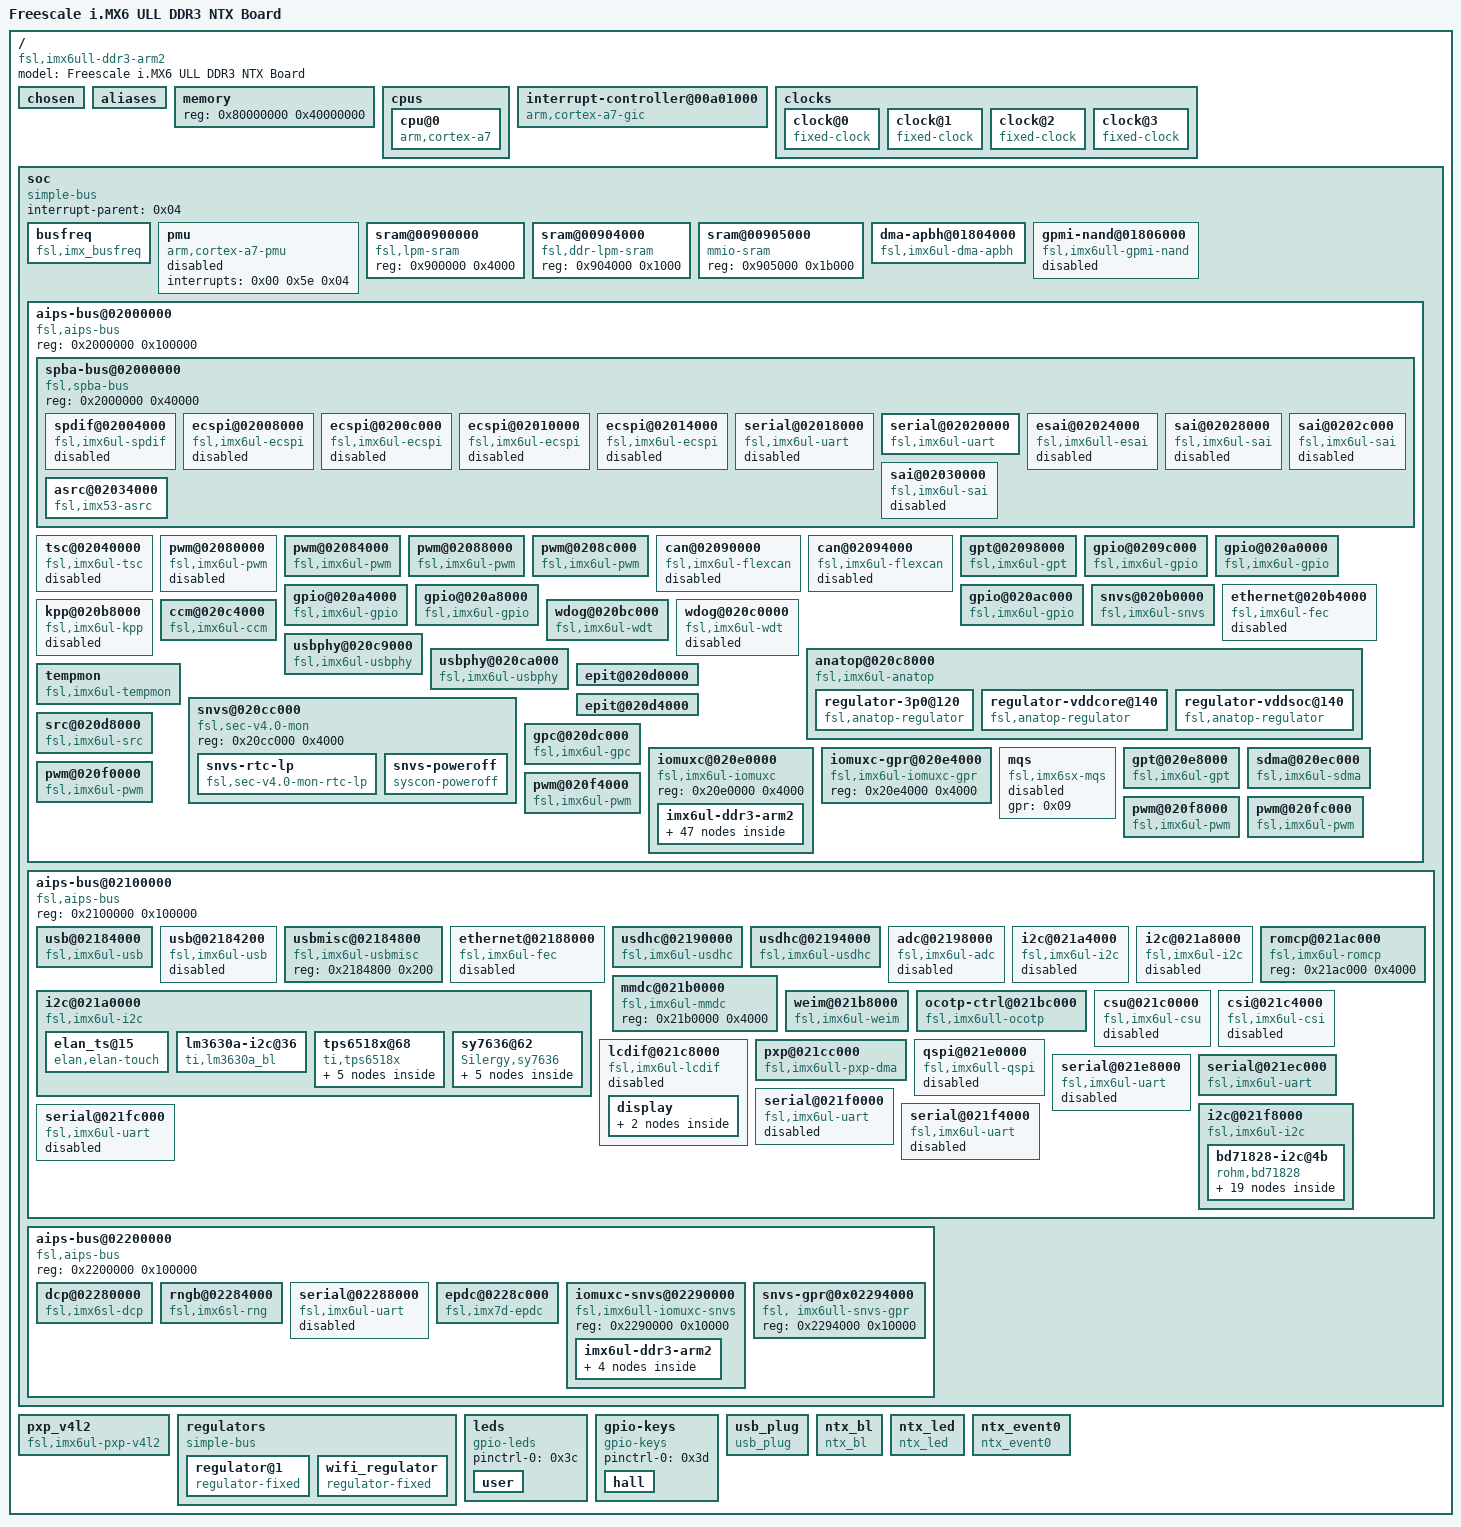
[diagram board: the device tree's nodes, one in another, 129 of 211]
/dts-v1/;

/ {
	#address-cells = <0x01>;
	#size-cells = <0x01>;
	model = "Freescale i.MX6 ULL DDR3 NTX Board";
	compatible = "fsl,imx6ull-ddr3-arm2\0fsl,imx6ull";

	chosen {
		stdout-path = "/soc/aips-bus@02000000/spba-bus@02000000/serial@02020000";
	};

	aliases {
		can0 = "/soc/aips-bus@02000000/can@02090000";
		can1 = "/soc/aips-bus@02000000/can@02094000";
		ethernet0 = "/soc/aips-bus@02100000/ethernet@02188000";
		ethernet1 = "/soc/aips-bus@02000000/ethernet@020b4000";
		gpio0 = "/soc/aips-bus@02000000/gpio@0209c000";
		gpio1 = "/soc/aips-bus@02000000/gpio@020a0000";
		gpio2 = "/soc/aips-bus@02000000/gpio@020a4000";
		gpio3 = "/soc/aips-bus@02000000/gpio@020a8000";
		gpio4 = "/soc/aips-bus@02000000/gpio@020ac000";
		i2c0 = "/soc/aips-bus@02100000/i2c@021a0000";
		i2c1 = "/soc/aips-bus@02100000/i2c@021a4000";
		i2c2 = "/soc/aips-bus@02100000/i2c@021a8000";
		i2c3 = "/soc/aips-bus@02100000/i2c@021f8000";
		mmc0 = "/soc/aips-bus@02100000/usdhc@02194000";
		mmc1 = "/soc/aips-bus@02100000/usdhc@02190000";
		serial0 = "/soc/aips-bus@02000000/spba-bus@02000000/serial@02020000";
		serial1 = "/soc/aips-bus@02100000/serial@021e8000";
		serial2 = "/soc/aips-bus@02100000/serial@021ec000";
		serial3 = "/soc/aips-bus@02100000/serial@021f0000";
		serial4 = "/soc/aips-bus@02100000/serial@021f4000";
		serial5 = "/soc/aips-bus@02100000/serial@021fc000";
		serial6 = "/soc/aips-bus@02000000/spba-bus@02000000/serial@02018000";
		serial7 = "/soc/aips-bus@02200000/serial@02288000";
		spi0 = "/soc/aips-bus@02000000/spba-bus@02000000/ecspi@02008000";
		spi1 = "/soc/aips-bus@02000000/spba-bus@02000000/ecspi@0200c000";
		spi2 = "/soc/aips-bus@02000000/spba-bus@02000000/ecspi@02010000";
		spi3 = "/soc/aips-bus@02000000/spba-bus@02000000/ecspi@02014000";
		usbphy0 = "/soc/aips-bus@02000000/usbphy@020c9000";
		usbphy1 = "/soc/aips-bus@02000000/usbphy@020ca000";
	};

	memory {
		device_type = "memory";
		reg = <0x80000000 0x40000000>;
	};

	cpus {
		#address-cells = <0x01>;
		#size-cells = <0x00>;

		cpu@0 {
			compatible = "arm,cortex-a7";
			device_type = "cpu";
			reg = <0x00>;
			clock-latency = <0xee6c>;
			operating-points = <0xdbba0 0x1312d0 0xc15c0 0x124f80 0x80e80 0x11edd8 0x60ae0 0x11edd8 0x30570 0x11edd8>;
			fsl,soc-operating-points = <0xdbba0 0x1312d0 0xc15c0 0x124f80 0x80e80 0x11edd8 0x60ae0 0x11edd8 0x30570 0x11edd8>;
			fsl,low-power-run;
			clocks = <0x01 0x5d 0x01 0x1a 0x01 0x26 0x01 0xdb 0x01 0x38 0x01 0x39 0x01 0x19 0x01 0x12 0x01 0x0b 0x01 0x04 0x01 0x03>;
			clock-names = "arm\0pll2_bus\0pll2_pfd2_396m\0secondary_sel\0step\0pll1_sw\0pll1_sys\0pll1_bypass\0pll1\0pll1_bypass_src\0osc";
			arm-supply = <0x02>;
			soc-supply = <0x03>;
		};
	};

	interrupt-controller@00a01000 {
		compatible = "arm,cortex-a7-gic";
		#interrupt-cells = <0x03>;
		interrupt-controller;
		reg = <0xa01000 0x1000 0xa02000 0x100>;
		linux,phandle = <0x13>;
		phandle = <0x13>;
	};

	clocks {
		#address-cells = <0x01>;
		#size-cells = <0x00>;

		clock@0 {
			compatible = "fixed-clock";
			reg = <0x00>;
			#clock-cells = <0x00>;
			clock-frequency = <0x8000>;
			clock-output-names = "ckil";
			linux,phandle = <0x0b>;
			phandle = <0x0b>;
		};

		clock@1 {
			compatible = "fixed-clock";
			reg = <0x01>;
			#clock-cells = <0x00>;
			clock-frequency = <0x16e3600>;
			clock-output-names = "osc";
			linux,phandle = <0x0c>;
			phandle = <0x0c>;
		};

		clock@2 {
			compatible = "fixed-clock";
			reg = <0x02>;
			#clock-cells = <0x00>;
			clock-frequency = <0x00>;
			clock-output-names = "ipp_di0";
			linux,phandle = <0x0d>;
			phandle = <0x0d>;
		};

		clock@3 {
			compatible = "fixed-clock";
			reg = <0x03>;
			#clock-cells = <0x00>;
			clock-frequency = <0x00>;
			clock-output-names = "ipp_di1";
			linux,phandle = <0x0e>;
			phandle = <0x0e>;
		};
	};

	soc {
		#address-cells = <0x01>;
		#size-cells = <0x01>;
		compatible = "simple-bus";
		interrupt-parent = <0x04>;
		ranges;

		busfreq {
			compatible = "fsl,imx_busfreq";
			clocks = <0x01 0x26 0x01 0x35 0x01 0x1a 0x01 0x5d 0x01 0x1b 0x01 0x55 0x01 0x3c 0x01 0x5e 0x01 0x3e 0x01 0x03 0x01 0x60 0x01 0xd4 0x01 0x56 0x01 0x3d 0x01 0x5f 0x01 0x3f 0x01 0x38 0x01 0xa3 0x01 0x04 0x01 0x12 0x01 0x19 0x01 0x39 0x01 0x0b>;
			clock-names = "pll2_pfd2_396m\0pll2_198m\0pll2_bus\0arm\0pll3_usb_otg\0periph\0periph_pre\0periph_clk2\0periph_clk2_sel\0osc\0ahb\0ocram\0periph2\0periph2_pre\0periph2_clk2\0periph2_clk2_sel\0step\0mmdc\0pll1_bypass_src\0pll1_bypass\0pll1_sys\0pll1_sw\0pll1";
			fsl,max_ddr_freq = <0x17d78400>;
		};

		pmu {
			compatible = "arm,cortex-a7-pmu";
			interrupts = <0x00 0x5e 0x04>;
			status = "disabled";
		};

		sram@00900000 {
			compatible = "fsl,lpm-sram";
			reg = <0x900000 0x4000>;
		};

		sram@00904000 {
			compatible = "fsl,ddr-lpm-sram";
			reg = <0x904000 0x1000>;
		};

		sram@00905000 {
			compatible = "mmio-sram";
			reg = <0x905000 0x1b000>;
			linux,phandle = <0x14>;
			phandle = <0x14>;
		};

		dma-apbh@01804000 {
			compatible = "fsl,imx6ul-dma-apbh\0fsl,imx28-dma-apbh";
			reg = <0x1804000 0x2000>;
			interrupts = <0x00 0x0d 0x04 0x00 0x0d 0x04 0x00 0x0d 0x04 0x00 0x0d 0x04>;
			interrupt-names = "gpmi0\0gpmi1\0gpmi2\0gpmi3";
			#dma-cells = <0x01>;
			dma-channels = <0x04>;
			clocks = <0x01 0x80>;
			linux,phandle = <0x05>;
			phandle = <0x05>;
		};

		gpmi-nand@01806000 {
			compatible = "fsl,imx6ull-gpmi-nand\0fsl, imx6ul-gpmi-nand";
			#address-cells = <0x01>;
			#size-cells = <0x01>;
			reg = <0x1806000 0x2000 0x1808000 0x4000>;
			reg-names = "gpmi-nand\0bch";
			interrupts = <0x00 0x0f 0x04>;
			interrupt-names = "bch";
			clocks = <0x01 0x85 0x01 0x86 0x01 0x84 0x01 0x83 0x01 0xdc>;
			clock-names = "gpmi_io\0gpmi_apb\0gpmi_bch\0gpmi_bch_apb\0per1_bch";
			dmas = <0x05 0x00>;
			dma-names = "rx-tx";
			status = "disabled";
			pinctrl-names = "default";
			pinctrl-0 = <0x06>;
			nand-on-flash-bbt;
		};

		aips-bus@02000000 {
			compatible = "fsl,aips-bus\0simple-bus";
			#address-cells = <0x01>;
			#size-cells = <0x01>;
			reg = <0x2000000 0x100000>;
			ranges;

			spba-bus@02000000 {
				compatible = "fsl,spba-bus\0simple-bus";
				#address-cells = <0x01>;
				#size-cells = <0x01>;
				reg = <0x2000000 0x40000>;
				ranges;

				spdif@02004000 {
					compatible = "fsl,imx6ul-spdif\0fsl,imx35-spdif";
					reg = <0x2004000 0x4000>;
					interrupts = <0x00 0x34 0x04>;
					dmas = <0x07 0x29 0x12 0x00 0x07 0x2a 0x12 0x00>;
					dma-names = "rx\0tx";
					clocks = <0x01 0xd5 0x01 0x03 0x01 0xbc 0x01 0x00 0x01 0x00 0x01 0x00 0x01 0x64 0x01 0x00 0x01 0x00 0x01 0xbb>;
					clock-names = "core\0rxtx0\0rxtx1\0rxtx2\0rxtx3\0rxtx4\0rxtx5\0rxtx6\0rxtx7\0dma";
					status = "disabled";
				};

				ecspi@02008000 {
					#address-cells = <0x01>;
					#size-cells = <0x00>;
					compatible = "fsl,imx6ul-ecspi\0fsl,imx51-ecspi";
					reg = <0x2008000 0x4000>;
					interrupts = <0x00 0x1f 0x04>;
					clocks = <0x01 0x8b 0x01 0x8b>;
					clock-names = "ipg\0per";
					dmas = <0x07 0x03 0x07 0x01 0x07 0x04 0x07 0x02>;
					dma-names = "rx\0tx";
					status = "disabled";
				};

				ecspi@0200c000 {
					#address-cells = <0x01>;
					#size-cells = <0x00>;
					compatible = "fsl,imx6ul-ecspi\0fsl,imx51-ecspi";
					reg = <0x200c000 0x4000>;
					interrupts = <0x00 0x20 0x04>;
					clocks = <0x01 0x8c 0x01 0x8c>;
					clock-names = "ipg\0per";
					dmas = <0x07 0x05 0x07 0x01 0x07 0x06 0x07 0x02>;
					dma-names = "rx\0tx";
					status = "disabled";
				};

				ecspi@02010000 {
					#address-cells = <0x01>;
					#size-cells = <0x00>;
					compatible = "fsl,imx6ul-ecspi\0fsl,imx51-ecspi";
					reg = <0x2010000 0x4000>;
					interrupts = <0x00 0x21 0x04>;
					clocks = <0x01 0x8d 0x01 0x8d>;
					clock-names = "ipg\0per";
					dmas = <0x07 0x07 0x07 0x01 0x07 0x08 0x07 0x02>;
					dma-names = "rx\0tx";
					status = "disabled";
				};

				ecspi@02014000 {
					#address-cells = <0x01>;
					#size-cells = <0x00>;
					compatible = "fsl,imx6ul-ecspi\0fsl,imx51-ecspi";
					reg = <0x2014000 0x4000>;
					interrupts = <0x00 0x22 0x04>;
					clocks = <0x01 0x8e 0x01 0x8e>;
					clock-names = "ipg\0per";
					dmas = <0x07 0x09 0x07 0x01 0x07 0x0a 0x07 0x02>;
					dma-names = "rx\0tx";
					status = "disabled";
				};

				serial@02018000 {
					compatible = "fsl,imx6ul-uart\0fsl,imx6q-uart\0fsl,imx21-uart";
					reg = <0x2018000 0x4000>;
					interrupts = <0x00 0x27 0x04>;
					clocks = <0x01 0xc9 0x01 0xca>;
					clock-names = "ipg\0per";
					dmas = <0x07 0x2b 0x04 0x00 0x07 0x2c 0x04 0x00>;
					dma-names = "rx\0tx";
					status = "disabled";
				};

				serial@02020000 {
					compatible = "fsl,imx6ul-uart\0fsl,imx6q-uart\0fsl,imx21-uart";
					reg = <0x2020000 0x4000>;
					interrupts = <0x00 0x1a 0x04>;
					clocks = <0x01 0xbd 0x01 0xbe>;
					clock-names = "ipg\0per";
					status = "okay";
					pinctrl-names = "default";
					pinctrl-0 = <0x08>;
				};

				esai@02024000 {
					compatible = "fsl,imx6ull-esai";
					reg = <0x2024000 0x4000>;
					interrupts = <0x00 0x33 0x04>;
					clocks = <0x01 0xe5 0x01 0xe4 0x01 0xe3 0x01 0xe5 0x01 0xbb>;
					clock-names = "core\0mem\0extal\0fsys\0dma";
					dmas = <0x07 0x00 0x15 0x00 0x07 0x2f 0x15 0x00>;
					dma-names = "rx\0tx";
					dma-source = <0x09 0x00 0x0e 0x00 0x0f>;
					status = "disabled";
				};

				sai@02028000 {
					compatible = "fsl,imx6ul-sai\0fsl,imx6sx-sai";
					reg = <0x2028000 0x4000>;
					interrupts = <0x00 0x61 0x04>;
					clocks = <0x01 0xb3 0x01 0x00 0x01 0xb2 0x01 0x00 0x01 0x00>;
					clock-names = "bus\0mclk0\0mclk1\0mclk2\0mclk3";
					dma-names = "rx\0tx";
					dmas = <0x07 0x23 0x18 0x00 0x07 0x24 0x18 0x00>;
					status = "disabled";
				};

				sai@0202c000 {
					compatible = "fsl,imx6ul-sai\0fsl,imx6sx-sai";
					reg = <0x202c000 0x4000>;
					interrupts = <0x00 0x62 0x04>;
					clocks = <0x01 0xb5 0x01 0x00 0x01 0xb4 0x01 0x00 0x01 0x00>;
					clock-names = "bus\0mclk0\0mclk1\0mclk2\0mclk3";
					dma-names = "rx\0tx";
					dmas = <0x07 0x25 0x18 0x00 0x07 0x26 0x18 0x00>;
					status = "disabled";
				};

				sai@02030000 {
					compatible = "fsl,imx6ul-sai\0fsl,imx6sx-sai";
					reg = <0x2030000 0x4000>;
					interrupts = <0x00 0x18 0x04>;
					clocks = <0x01 0xb7 0x01 0x00 0x01 0xb6 0x01 0x00 0x01 0x00>;
					clock-names = "bus\0mclk0\0mclk1\0mclk2\0mclk3";
					dma-names = "rx\0tx";
					dmas = <0x07 0x27 0x18 0x00 0x07 0x28 0x18 0x00>;
					status = "disabled";
				};

				asrc@02034000 {
					compatible = "fsl,imx53-asrc";
					reg = <0x2034000 0x4000>;
					interrupts = <0x00 0x32 0x04>;
					clocks = <0x01 0x81 0x01 0x82 0x01 0x00 0x01 0x00 0x01 0x00 0x01 0x00 0x01 0x00 0x01 0x00 0x01 0x00 0x01 0x00 0x01 0x00 0x01 0x00 0x01 0x00 0x01 0x00 0x01 0x00 0x01 0xbc 0x01 0x00 0x01 0x00 0x01 0xbb>;
					clock-names = "mem\0ipg\0asrck_0\0asrck_1\0asrck_2\0asrck_3\0asrck_4\0asrck_5\0asrck_6\0asrck_7\0asrck_8\0asrck_9\0asrck_a\0asrck_b\0asrck_c\0asrck_d\0asrck_e\0asrck_f\0dma";
					dmas = <0x07 0x11 0x17 0x01 0x07 0x12 0x17 0x01 0x07 0x13 0x17 0x01 0x07 0x14 0x17 0x01 0x07 0x15 0x17 0x01 0x07 0x16 0x17 0x01>;
					dma-names = "rxa\0rxb\0rxc\0txa\0txb\0txc";
					fsl,asrc-rate = <0xbb80>;
					fsl,asrc-width = <0x10>;
					status = "okay";
				};
			};

			tsc@02040000 {
				compatible = "fsl,imx6ul-tsc";
				reg = <0x2040000 0x4000 0x219c000 0x4000>;
				interrupts = <0x00 0x03 0x04 0x00 0x65 0x04>;
				clocks = <0x01 0x64 0x01 0x7c>;
				clock-names = "tsc\0adc";
				status = "disabled";
			};

			pwm@02080000 {
				compatible = "fsl,imx6ul-pwm\0fsl,imx27-pwm";
				reg = <0x2080000 0x4000>;
				interrupts = <0x00 0x53 0x04>;
				clocks = <0x01 0xa7 0x01 0xa7>;
				clock-names = "ipg\0per";
				#pwm-cells = <0x02>;
				pinctrl-names = "default";
				pinctrl-0 = <0x0a>;
				status = "disabled";
			};

			pwm@02084000 {
				compatible = "fsl,imx6ul-pwm\0fsl,imx27-pwm";
				reg = <0x2084000 0x4000>;
				interrupts = <0x00 0x54 0x04>;
				clocks = <0x01 0x00 0x01 0x00>;
				clock-names = "ipg\0per";
				#pwm-cells = <0x02>;
			};

			pwm@02088000 {
				compatible = "fsl,imx6ul-pwm\0fsl,imx27-pwm";
				reg = <0x2088000 0x4000>;
				interrupts = <0x00 0x55 0x04>;
				clocks = <0x01 0xa9 0x01 0xa9>;
				clock-names = "ipg\0per";
				#pwm-cells = <0x02>;
			};

			pwm@0208c000 {
				compatible = "fsl,imx6ul-pwm\0fsl,imx27-pwm";
				reg = <0x208c000 0x4000>;
				interrupts = <0x00 0x56 0x04>;
				clocks = <0x01 0x00 0x01 0x00>;
				clock-names = "ipg\0per";
				#pwm-cells = <0x02>;
			};

			can@02090000 {
				compatible = "fsl,imx6ul-flexcan\0fsl,imx6q-flexcan";
				reg = <0x2090000 0x4000>;
				interrupts = <0x00 0x6e 0x04>;
				clocks = <0x01 0x94 0x01 0x95>;
				clock-names = "ipg\0per";
				stop-mode = <0x09 0x10 0x01 0x10 0x11>;
				status = "disabled";
			};

			can@02094000 {
				compatible = "fsl,imx6ul-flexcan\0fsl,imx6q-flexcan";
				reg = <0x2094000 0x4000>;
				interrupts = <0x00 0x6f 0x04>;
				clocks = <0x01 0x96 0x01 0x97>;
				clock-names = "ipg\0per";
				stop-mode = <0x09 0x10 0x02 0x10 0x12>;
				status = "disabled";
			};

			gpt@02098000 {
				compatible = "fsl,imx6ul-gpt\0fsl,imx31-gpt";
				reg = <0x2098000 0x4000>;
				interrupts = <0x00 0x37 0x04>;
				clocks = <0x01 0x98 0x01 0x99>;
				clock-names = "ipg\0per";
			};

			gpio@0209c000 {
				compatible = "fsl,imx6ul-gpio\0fsl,imx35-gpio";
				reg = <0x209c000 0x4000>;
				interrupts = <0x00 0x42 0x04 0x00 0x43 0x04>;
				gpio-controller;
				#gpio-cells = <0x02>;
				interrupt-controller;
				#interrupt-cells = <0x02>;
				linux,phandle = <0x27>;
				phandle = <0x27>;
			};

			gpio@020a0000 {
				compatible = "fsl,imx6ul-gpio\0fsl,imx35-gpio";
				reg = <0x20a0000 0x4000>;
				interrupts = <0x00 0x44 0x04 0x00 0x45 0x04>;
				gpio-controller;
				#gpio-cells = <0x02>;
				interrupt-controller;
				#interrupt-cells = <0x02>;
				linux,phandle = <0x29>;
				phandle = <0x29>;
			};

			gpio@020a4000 {
				compatible = "fsl,imx6ul-gpio\0fsl,imx35-gpio";
				reg = <0x20a4000 0x4000>;
				interrupts = <0x00 0x46 0x04 0x00 0x47 0x04>;
				gpio-controller;
				#gpio-cells = <0x02>;
				interrupt-controller;
				#interrupt-cells = <0x02>;
				linux,phandle = <0x28>;
				phandle = <0x28>;
			};

			gpio@020a8000 {
				compatible = "fsl,imx6ul-gpio\0fsl,imx35-gpio";
				reg = <0x20a8000 0x4000>;
				interrupts = <0x00 0x48 0x04 0x00 0x49 0x04>;
				gpio-controller;
				#gpio-cells = <0x02>;
				interrupt-controller;
				#interrupt-cells = <0x02>;
				linux,phandle = <0x36>;
				phandle = <0x36>;
			};

			gpio@020ac000 {
				compatible = "fsl,imx6ul-gpio\0fsl,imx35-gpio";
				reg = <0x20ac000 0x4000>;
				interrupts = <0x00 0x4a 0x04 0x00 0x4b 0x04>;
				gpio-controller;
				#gpio-cells = <0x02>;
				interrupt-controller;
				#interrupt-cells = <0x02>;
				linux,phandle = <0x35>;
				phandle = <0x35>;
			};

			snvs@020b0000 {
				compatible = "fsl,imx6ul-snvs";
				reg = <0x20b0000 0x4000>;
				interrupts = <0x00 0x04 0x04>;
			};

			ethernet@020b4000 {
				compatible = "fsl,imx6ul-fec\0fsl,imx6q-fec";
				reg = <0x20b4000 0x4000>;
				interrupts = <0x00 0x78 0x04 0x00 0x79 0x04>;
				clocks = <0x01 0x90 0x01 0x91 0x01 0x30 0x01 0x2e 0x01 0x2e>;
				clock-names = "ipg\0ahb\0ptp\0enet_clk_ref\0enet_out";
				stop-mode = <0x09 0x10 0x04>;
				fsl,num-tx-queues = <0x01>;
				fsl,num-rx-queues = <0x01>;
				fsl,magic-packet;
				fsl,wakeup_irq = <0x00>;
				status = "disabled";
			};

			kpp@020b8000 {
				compatible = "fsl,imx6ul-kpp\0fsl,imx21-kpp";
				reg = <0x20b8000 0x4000>;
				interrupts = <0x00 0x52 0x04>;
				clocks = <0x01 0x00>;
				status = "disabled";
			};

			wdog@020bc000 {
				compatible = "fsl,imx6ul-wdt\0fsl,imx21-wdt";
				reg = <0x20bc000 0x4000>;
				interrupts = <0x00 0x50 0x04>;
				clocks = <0x01 0xd0>;
			};

			wdog@020c0000 {
				compatible = "fsl,imx6ul-wdt\0fsl,imx21-wdt";
				reg = <0x20c0000 0x4000>;
				interrupts = <0x00 0x51 0x04>;
				clocks = <0x01 0xd1>;
				status = "disabled";
			};

			ccm@020c4000 {
				compatible = "fsl,imx6ul-ccm";
				reg = <0x20c4000 0x4000>;
				interrupts = <0x00 0x57 0x04 0x00 0x58 0x04>;
				#clock-cells = <0x01>;
				clocks = <0x0b 0x0c 0x0d 0x0e>;
				clock-names = "ckil\0osc\0ipp_di0\0ipp_di1";
				linux,phandle = <0x01>;
				phandle = <0x01>;
			};

			anatop@020c8000 {
				compatible = "fsl,imx6ul-anatop\0fsl,imx6q-anatop\0syscon\0simple-bus";
				reg = <0x20c8000 0x1000>;
				interrupts = <0x00 0x31 0x04 0x00 0x36 0x04 0x00 0x7f 0x04>;
				linux,phandle = <0x10>;
				phandle = <0x10>;

				regulator-3p0@120 {
					compatible = "fsl,anatop-regulator";
					regulator-name = "vdd3p0";
					regulator-min-microvolt = <0x280de8>;
					regulator-max-microvolt = <0x33e140>;
					anatop-reg-offset = <0x120>;
					anatop-vol-bit-shift = <0x08>;
					anatop-vol-bit-width = <0x05>;
					anatop-min-bit-val = <0x00>;
					anatop-min-voltage = <0x280de8>;
					anatop-max-voltage = <0x33e140>;
					anatop-enable-bit = <0x00>;
					linux,phandle = <0x0f>;
					phandle = <0x0f>;
				};

				regulator-vddcore@140 {
					compatible = "fsl,anatop-regulator";
					regulator-name = "cpu";
					regulator-min-microvolt = <0xb1008>;
					regulator-max-microvolt = <0x162010>;
					regulator-always-on;
					anatop-reg-offset = <0x140>;
					anatop-vol-bit-shift = <0x00>;
					anatop-vol-bit-width = <0x05>;
					anatop-delay-reg-offset = <0x170>;
					anatop-delay-bit-shift = <0x18>;
					anatop-delay-bit-width = <0x02>;
					anatop-min-bit-val = <0x01>;
					anatop-min-voltage = <0xb1008>;
					anatop-max-voltage = <0x162010>;
					linux,phandle = <0x02>;
					phandle = <0x02>;
				};

				regulator-vddsoc@140 {
					compatible = "fsl,anatop-regulator";
					regulator-name = "vddsoc";
					regulator-min-microvolt = <0xb1008>;
					regulator-max-microvolt = <0x162010>;
					regulator-always-on;
					anatop-reg-offset = <0x140>;
					anatop-vol-bit-shift = <0x12>;
					anatop-vol-bit-width = <0x05>;
					anatop-delay-reg-offset = <0x170>;
					anatop-delay-bit-shift = <0x1c>;
					anatop-delay-bit-width = <0x02>;
					anatop-min-bit-val = <0x01>;
					anatop-min-voltage = <0xb1008>;
					anatop-max-voltage = <0x162010>;
					linux,phandle = <0x03>;
					phandle = <0x03>;
				};
			};

			usbphy@020c9000 {
				compatible = "fsl,imx6ul-usbphy\0fsl,imx23-usbphy";
				reg = <0x20c9000 0x1000>;
				interrupts = <0x00 0x2c 0x04>;
				clocks = <0x01 0x20>;
				phy-3p0-supply = <0x0f>;
				fsl,anatop = <0x10>;
				linux,phandle = <0x15>;
				phandle = <0x15>;
			};

			usbphy@020ca000 {
				compatible = "fsl,imx6ul-usbphy\0fsl,imx23-usbphy";
				reg = <0x20ca000 0x1000>;
				interrupts = <0x00 0x2d 0x04>;
				clocks = <0x01 0x21>;
				phy-3p0-supply = <0x0f>;
				fsl,anatop = <0x10>;
				linux,phandle = <0x17>;
				phandle = <0x17>;
			};

			tempmon {
				compatible = "fsl,imx6ul-tempmon\0fsl,imx6sx-tempmon";
				interrupts = <0x00 0x31 0x04>;
				fsl,tempmon = <0x10>;
				fsl,tempmon-data = <0x11>;
				clocks = <0x01 0x1b>;
			};

			snvs@020cc000 {
				compatible = "fsl,sec-v4.0-mon\0syscon\0simple-mfd";
				reg = <0x20cc000 0x4000>;
				linux,phandle = <0x12>;
				phandle = <0x12>;

				snvs-rtc-lp {
					compatible = "fsl,sec-v4.0-mon-rtc-lp";
					regmap = <0x12>;
					offset = <0x34>;
					interrupts = <0x00 0x13 0x04 0x00 0x14 0x04>;
				};

				snvs-poweroff {
					compatible = "syscon-poweroff";
					regmap = <0x12>;
					offset = <0x38>;
					mask = <0x61>;
				};
			};

			epit@020d0000 {
				reg = <0x20d0000 0x4000>;
				interrupts = <0x00 0x38 0x04>;
			};

			epit@020d4000 {
				reg = <0x20d4000 0x4000>;
				interrupts = <0x00 0x39 0x04>;
			};

			src@020d8000 {
				compatible = "fsl,imx6ul-src\0fsl,imx51-src";
				reg = <0x20d8000 0x4000>;
				interrupts = <0x00 0x5b 0x04 0x00 0x60 0x04>;
				#reset-cells = <0x01>;
			};

			gpc@020dc000 {
				compatible = "fsl,imx6ul-gpc\0fsl,imx6q-gpc";
				reg = <0x20dc000 0x4000>;
				interrupt-controller;
				#interrupt-cells = <0x03>;
				interrupts = <0x00 0x59 0x04>;
				interrupt-parent = <0x13>;
				fsl,mf-mix-wakeup-irq = <0xfc00000 0x7d00 0x00 0x1400640>;
				fsl,cpu_pupscr_sw2iso = <0x01>;
				fsl,cpu_pupscr_sw = <0x00>;
				fsl,cpu_pdnscr_iso2sw = <0x01>;
				fsl,cpu_pdnscr_iso = <0x01>;
				fsl,ldo-bypass = <0x00>;
				linux,phandle = <0x04>;
				phandle = <0x04>;
			};

			iomuxc@020e0000 {
				compatible = "fsl,imx6ul-iomuxc";
				reg = <0x20e0000 0x4000>;
				pinctrl-names = "default\0sleep";

				imx6ul-ddr3-arm2 {

					adc1grp {
						fsl,pins = <0x5c 0x2e8 0x00 0x05 0x00 0xb0 0x60 0x2ec 0x00 0x05 0x00 0xb0>;
					};

					csi1grp {
						fsl,pins = <0x1d4 0x460 0x00 0x00 0x00 0x1b088 0x1d8 0x464 0x528 0x00 0x01 0x1b088 0x1dc 0x468 0x52c 0x00 0x00 0x1b088 0x1e0 0x46c 0x524 0x00 0x00 0x1b088 0x1e4 0x470 0x4c4 0x00 0x00 0x1b088 0x1e8 0x474 0x4c8 0x00 0x00 0x1b088 0x1ec 0x478 0x4d8 0x00 0x01 0x1b088 0x1f0 0x47c 0x4cc 0x00 0x00 0x1b088 0x1f4 0x480 0x4dc 0x00 0x01 0x1b088 0x1f8 0x484 0x4e0 0x00 0x01 0x1b088 0x1fc 0x488 0x4e4 0x00 0x01 0x1b088 0x200 0x48c 0x4e8 0x00 0x01 0x1b088>;
					};

					ecspi1_cs_grp-1 {
						fsl,pins = <0x1f8 0x484 0x00 0x05 0x00 0x10b0>;
					};

					ecspi1grp-1 {
						fsl,pins = <0x1fc 0x488 0x53c 0x03 0x01 0x10b0 0x200 0x48c 0x538 0x03 0x01 0x10b0 0x1f4 0x480 0x534 0x03 0x01 0x10b0>;
					};

					enet1grp {
						fsl,pins = <0xcc 0x358 0x00 0x00 0x00 0x1b0b0 0xe0 0x36c 0x00 0x00 0x00 0x1b0b0 0xc4 0x350 0x00 0x00 0x00 0x1b0b0 0xc8 0x354 0x00 0x00 0x00 0x1b0b0 0xd8 0x364 0x00 0x00 0x00 0x1b0b0 0xd0 0x35c 0x00 0x00 0x00 0x1b0b0 0xd4 0x360 0x00 0x00 0x00 0x1b0b0 0xdc 0x368 0x574 0x04 0x02 0x4001b0a0>;
					};

					enet2grp {
						fsl,pins = <0x78 0x304 0x00 0x01 0x00 0x1b098 0x74 0x300 0x580 0x01 0x00 0x1b0b0 0xf0 0x37c 0x00 0x00 0x00 0x1b0a0 0xf4 0x380 0x00 0x00 0x00 0x1b0a0 0xb4 0x340 0x00 0x01 0x00 0x1b0a0 0xb8 0x344 0x00 0x01 0x00 0x1b0a0 0xfc 0x388 0x00 0x00 0x00 0x4001b0a8 0xf8 0x384 0x00 0x00 0x00 0x1b0b0 0xe4 0x370 0x00 0x00 0x00 0x1b0b0 0xe8 0x374 0x00 0x00 0x00 0x1b0b0 0xa4 0x330 0x00 0x01 0x00 0x1b0b0 0xa8 0x334 0x00 0x01 0x00 0x1b0b0 0xec 0x378 0x00 0x00 0x00 0x1b0b0 0x100 0x38c 0x00 0x00 0x00 0x1b0b0 0xac 0x338 0x00 0x01 0x00 0x4001b0a8 0xc0 0x34c 0x00 0x01 0x00 0x1b0b0 0xbc 0x348 0x00 0x01 0x00 0x1b0b0>;
					};

					epdcgrp0 {
						fsl,pins = <0xe4 0x370 0x00 0x09 0x00 0x10b1 0xe8 0x374 0x00 0x09 0x00 0x10b1 0xec 0x378 0x00 0x09 0x00 0x10b1 0xf0 0x37c 0x00 0x09 0x00 0x10b1 0xf4 0x380 0x00 0x09 0x00 0x10b1 0xf8 0x384 0x00 0x09 0x00 0x10b1 0xfc 0x388 0x00 0x09 0x00 0x10b1 0x100 0x38c 0x00 0x09 0x00 0x10b1 0x104 0x390 0x00 0x09 0x00 0x10b1 0x108 0x394 0x00 0x09 0x00 0x10b1 0x10c 0x398 0x00 0x09 0x00 0x10b1 0x110 0x39c 0x00 0x09 0x00 0x10b1 0x118 0x3a4 0x00 0x09 0x00 0x10b1 0x11c 0x3a8 0x00 0x09 0x00 0x10b1 0x120 0x3ac 0x00 0x09 0x00 0x10b1 0x124 0x3b0 0x00 0x09 0x00 0x10b1 0x128 0x3b4 0x00 0x09 0x00 0x10b1 0x12c 0x3b8 0x00 0x09 0x00 0x10b1 0x130 0x3bc 0x00 0x09 0x00 0x10b1 0x134 0x3c0 0x00 0x09 0x00 0x10b1 0x150 0x3dc 0x00 0x09 0x00 0x10b1 0x154 0x3e0 0x00 0x09 0x00 0x10b1 0x158 0x3e4 0x00 0x09 0x00 0x10b1 0x15c 0x3e8 0x00 0x09 0x00 0x10b1 0x114 0x3a0 0x00 0x09 0x00 0x10b1>;
						linux,phandle = <0x37>;
						phandle = <0x37>;
					};

					esaigrp {
						fsl,pins = <0x1e4 0x470 0x00 0x09 0x00 0x1b0b0 0x1e8 0x474 0x00 0x09 0x00 0x1b0b0 0x1f4 0x480 0x00 0x09 0x00 0x1b0b0 0x1f8 0x484 0x00 0x09 0x00 0x1b0b0 0x200 0x48c 0x00 0x09 0x00 0x1b0b0 0x1e0 0x46c 0x00 0x09 0x00 0x1b0b0 0x1d8 0x464 0x00 0x09 0x00 0x1b0b0 0x1d4 0x460 0x00 0x09 0x00 0x1b0b0 0x1ec 0x478 0x00 0x09 0x00 0x1b0b0 0x1f0 0x47c 0x00 0x09 0x00 0x1b0b0 0x1fc 0x488 0x00 0x09 0x00 0x1b0b0 0x1dc 0x468 0x00 0x09 0x00 0x1b0b0>;
					};

					flexcan2grp {
						fsl,pins = <0xa0 0x32c 0x588 0x02 0x00 0x1b020 0x9c 0x328 0x00 0x02 0x00 0x1b020 0x58 0x2e4 0x00 0x05 0x00 0x17059>;
					};

					gpmi-nand-1 {
						fsl,pins = <0x1b4 0x440 0x00 0x00 0x00 0xb0b1 0x1a0 0x42c 0x00 0x00 0x00 0xb0b1 0x1a4 0x430 0x00 0x00 0x00 0xb0b1 0x1a8 0x434 0x00 0x00 0x00 0xb000 0x1ac 0x438 0x00 0x00 0x00 0xb0b1 0x1b0 0x43c 0x00 0x00 0x00 0xb0b1 0x178 0x404 0x00 0x00 0x00 0xb0b1 0x17c 0x408 0x00 0x00 0x00 0xb0b1 0x180 0x40c 0x00 0x00 0x00 0xb0b1 0x184 0x410 0x00 0x00 0x00 0xb0b1 0x188 0x414 0x00 0x00 0x00 0xb0b1 0x18c 0x418 0x00 0x00 0x00 0xb0b1 0x190 0x41c 0x00 0x00 0x00 0xb0b1 0x194 0x420 0x00 0x00 0x00 0xb0b1 0x198 0x424 0x00 0x00 0x00 0xb0b1 0x19c 0x428 0x00 0x00 0x00 0xb0b1>;
						linux,phandle = <0x06>;
						phandle = <0x06>;
					};

					i2c1grp {
						fsl,pins = <0xb4 0x340 0x5a4 0x02 0x01 0x4001f8b0 0xb8 0x344 0x5a8 0x02 0x02 0x4001f8b0>;
						linux,phandle = <0x20>;
						phandle = <0x20>;
					};

					i2c1grp_sleep {
						fsl,pins = <0xb4 0x340 0x5a4 0x02 0x01 0x400108b0 0xb8 0x344 0x5a8 0x02 0x02 0x400108b0>;
						linux,phandle = <0x24>;
						phandle = <0x24>;
					};

					i2c4grp {
						fsl,pins = <0x94 0x320 0x5bc 0x02 0x00 0x4001f8b0 0x98 0x324 0x5c0 0x02 0x00 0x4001f8b0>;
						linux,phandle = <0x32>;
						phandle = <0x32>;
					};

					i2c4grp_sleep {
						fsl,pins = <0x94 0x320 0x5bc 0x02 0x00 0x400108b0 0x98 0x324 0x5c0 0x02 0x00 0x400108b0>;
					};

					lcdifdatgrp {
						fsl,pins = <0x118 0x3a4 0x00 0x00 0x00 0x79 0x11c 0x3a8 0x00 0x00 0x00 0x79 0x120 0x3ac 0x00 0x00 0x00 0x79 0x124 0x3b0 0x00 0x00 0x00 0x79 0x128 0x3b4 0x00 0x00 0x00 0x79 0x12c 0x3b8 0x00 0x00 0x00 0x79 0x130 0x3bc 0x00 0x00 0x00 0x79 0x134 0x3c0 0x00 0x00 0x00 0x79 0x138 0x3c4 0x00 0x00 0x00 0x79 0x13c 0x3c8 0x00 0x00 0x00 0x79 0x140 0x3cc 0x00 0x00 0x00 0x79 0x144 0x3d0 0x00 0x00 0x00 0x79 0x148 0x3d4 0x00 0x00 0x00 0x79 0x14c 0x3d8 0x00 0x00 0x00 0x79 0x150 0x3dc 0x00 0x00 0x00 0x79 0x154 0x3e0 0x00 0x00 0x00 0x79 0x158 0x3e4 0x00 0x00 0x00 0x79 0x15c 0x3e8 0x00 0x00 0x00 0x79 0x160 0x3ec 0x00 0x00 0x00 0x79 0x164 0x3f0 0x00 0x00 0x00 0x79 0x168 0x3f4 0x00 0x00 0x00 0x79 0x16c 0x3f8 0x00 0x00 0x00 0x79 0x170 0x3fc 0x00 0x00 0x00 0x79 0x174 0x400 0x00 0x00 0x00 0x79>;
						linux,phandle = <0x2a>;
						phandle = <0x2a>;
					};

					lcdifctrlgrp {
						fsl,pins = <0x104 0x390 0x00 0x00 0x00 0x79 0x108 0x394 0x00 0x00 0x00 0x79 0x10c 0x398 0x5dc 0x00 0x00 0x79 0x110 0x39c 0x00 0x00 0x00 0x79 0x114 0x3a0 0x00 0x00 0x00 0x79>;
						linux,phandle = <0x2b>;
						phandle = <0x2b>;
					};

					mqsgrp {
						fsl,pins = <0x50 0x2dc 0x00 0x06 0x00 0x11088 0x4c 0x2d8 0x00 0x06 0x00 0x11088>;
					};

					pmw1grp {
						fsl,pins = <0xc4 0x350 0x00 0x02 0x00 0x110b0>;
						linux,phandle = <0x0a>;
						phandle = <0x0a>;
					};

					qspigrp {
						fsl,pins = <0x1a4 0x430 0x00 0x02 0x00 0x70a1 0x1a8 0x434 0x00 0x02 0x00 0x70a1 0x1ac 0x438 0x00 0x02 0x00 0x70a1 0x1b0 0x43c 0x00 0x02 0x00 0x70a1 0x1b4 0x440 0x00 0x02 0x00 0x70a1 0x1b8 0x444 0x00 0x02 0x00 0x70a1>;
						linux,phandle = <0x2e>;
						phandle = <0x2e>;
					};

					sai2grp {
						fsl,pins = <0x1c4 0x450 0x5fc 0x02 0x01 0x1b0b0 0x1c8 0x454 0x5f8 0x02 0x01 0x1b0b0 0x1cc 0x458 0x5f4 0x02 0x01 0x110b0 0x1d0 0x45c 0x00 0x02 0x00 0x110b0 0x1c0 0x44c 0x5f0 0x02 0x01 0x1b0b0>;
					};

					uart1grp {
						fsl,pins = <0x84 0x310 0x00 0x00 0x00 0x1b0b1 0x88 0x314 0x624 0x00 0x03 0x1b0b1>;
						linux,phandle = <0x08>;
						phandle = <0x08>;
					};

					uart3grp {
						fsl,pins = <0xa4 0x330 0x00 0x00 0x00 0x1b0b1 0xa8 0x334 0x634 0x00 0x01 0x1b0b1 0xac 0x338 0x00 0x00 0x00 0x1b0b1 0xb0 0x33c 0x630 0x00 0x01 0x1b0b1>;
					};

					uart3dtegrp {
						fsl,pins = <0xa4 0x330 0x634 0x00 0x00 0xb0b0 0xa8 0x334 0x00 0x00 0x00 0xb0b0 0xac 0x338 0x630 0x00 0x00 0xb0b0 0xb0 0x33c 0x00 0x00 0x00 0xb0b0>;
						linux,phandle = <0x2f>;
						phandle = <0x2f>;
					};

					uart3dtesleepgrp {
						fsl,pins = <0xa4 0x330 0x634 0x00 0x00 0x80000000 0xa8 0x334 0x00 0x00 0x00 0x80000000 0xac 0x338 0x630 0x00 0x00 0x80000000 0xb0 0x33c 0x00 0x00 0x00 0x80000000>;
						linux,phandle = <0x31>;
						phandle = <0x31>;
					};

					btgrp {
						fsl,pins = <0x1e8 0x474 0x00 0x05 0x00 0x80000000 0x1f0 0x47c 0x00 0x05 0x00 0x80000000 0x1ec 0x478 0x00 0x05 0x00 0x80000000>;
						linux,phandle = <0x30>;
						phandle = <0x30>;
					};

					usbotg1idgrp {
						fsl,pins = <0x5c 0x2e8 0x4b8 0x02 0x00 0x17059>;
					};

					usbotg1grp {
						fsl,pins = <0x6c 0x2f8 0x00 0x05 0x00 0x10b0>;
					};

					usdhc1grp {
						fsl,pins = <0x1bc 0x448 0x00 0x00 0x00 0x11059 0x1c0 0x44c 0x00 0x00 0x00 0x11059 0x1c4 0x450 0x00 0x00 0x00 0x11059 0x1c8 0x454 0x00 0x00 0x00 0x11059 0x1cc 0x458 0x00 0x00 0x00 0x11059 0x1d0 0x45c 0x00 0x00 0x00 0x11059>;
						linux,phandle = <0x18>;
						phandle = <0x18>;
					};

					usdhc1grp_sleep {
						fsl,pins = <0x1bc 0x448 0x00 0x05 0x00 0x100c1 0x1c0 0x44c 0x00 0x05 0x00 0x100c1 0x1c4 0x450 0x00 0x05 0x00 0x100c1 0x1c8 0x454 0x00 0x05 0x00 0x100c1 0x1cc 0x458 0x00 0x05 0x00 0x100c1 0x1d0 0x45c 0x00 0x05 0x00 0x100c1>;
						linux,phandle = <0x1c>;
						phandle = <0x1c>;
					};

					usdhc1grp100mhz {
						fsl,pins = <0x1bc 0x448 0x00 0x00 0x00 0x170b9 0x1c0 0x44c 0x00 0x00 0x00 0x170b9 0x1c4 0x450 0x00 0x00 0x00 0x170b9 0x1c8 0x454 0x00 0x00 0x00 0x170b9 0x1cc 0x458 0x00 0x00 0x00 0x170b9 0x1d0 0x45c 0x00 0x00 0x00 0x170b9>;
						linux,phandle = <0x1a>;
						phandle = <0x1a>;
					};

					usdhc1grp200mhz {
						fsl,pins = <0x1bc 0x448 0x00 0x00 0x00 0x170f9 0x1c0 0x44c 0x00 0x00 0x00 0x170f9 0x1c4 0x450 0x00 0x00 0x00 0x170f9 0x1c8 0x454 0x00 0x00 0x00 0x170f9 0x1cc 0x458 0x00 0x00 0x00 0x170f9 0x1d0 0x45c 0x00 0x00 0x00 0x170f9>;
						linux,phandle = <0x1b>;
						phandle = <0x1b>;
					};

					usdhc1_8bit_grp {
						fsl,pins = <0x1bc 0x448 0x00 0x00 0x00 0x17059 0x1c0 0x44c 0x00 0x00 0x00 0x10059 0x1c4 0x450 0x00 0x00 0x00 0x17059 0x1c8 0x454 0x00 0x00 0x00 0x17059 0x1cc 0x458 0x00 0x00 0x00 0x17059 0x1d0 0x45c 0x00 0x00 0x00 0x17059 0x1a8 0x434 0x00 0x01 0x00 0x17059 0x1ac 0x438 0x00 0x01 0x00 0x17059 0x1b0 0x43c 0x00 0x01 0x00 0x17059 0x1b4 0x440 0x00 0x01 0x00 0x17059>;
					};

					usdhc1_8bit_100mhz_grp {
						fsl,pins = <0x1bc 0x448 0x00 0x00 0x00 0x170b9 0x1c0 0x44c 0x00 0x00 0x00 0x100b9 0x1c4 0x450 0x00 0x00 0x00 0x170b9 0x1c8 0x454 0x00 0x00 0x00 0x170b9 0x1cc 0x458 0x00 0x00 0x00 0x170b9 0x1d0 0x45c 0x00 0x00 0x00 0x170b9 0x1a8 0x434 0x00 0x01 0x00 0x170b9 0x1ac 0x438 0x00 0x01 0x00 0x170b9 0x1b0 0x43c 0x00 0x01 0x00 0x170b9 0x1b4 0x440 0x00 0x01 0x00 0x170b9>;
					};

					usdhc1_8bit_200mhz_grp {
						fsl,pins = <0x1bc 0x448 0x00 0x00 0x00 0x170f9 0x1c0 0x44c 0x00 0x00 0x00 0x100f9 0x1c4 0x450 0x00 0x00 0x00 0x170f9 0x1c8 0x454 0x00 0x00 0x00 0x170f9 0x1cc 0x458 0x00 0x00 0x00 0x170f9 0x1d0 0x45c 0x00 0x00 0x00 0x170f9 0x1a8 0x434 0x00 0x01 0x00 0x170f9 0x1ac 0x438 0x00 0x01 0x00 0x170f9 0x1b0 0x43c 0x00 0x01 0x00 0x170f9 0x1b4 0x440 0x00 0x01 0x00 0x170f9>;
					};

					usdhc1_cd_wp_grp {
						fsl,pins = <0x90 0x31c 0x00 0x05 0x00 0x17059 0x8c 0x318 0x00 0x05 0x00 0x17059>;
					};

					elan_ts_gpio_grp {
						fsl,pins = <0x78 0x304 0x00 0x05 0x00 0x17059 0x74 0x300 0x00 0x05 0x00 0x10059>;
						linux,phandle = <0x22>;
						phandle = <0x22>;
					};

					elan_ts_gpio_grp_sleep {
						fsl,pins = <0x78 0x304 0x00 0x05 0x00 0x10059 0x74 0x300 0x00 0x05 0x00 0x10059>;
						linux,phandle = <0x26>;
						phandle = <0x26>;
					};

					tps65185_gpio_grp {
						fsl,pins = <0x13c 0x3c8 0x00 0x15 0x00 0x10059 0x164 0x3f0 0x00 0x15 0x00 0x10059 0x148 0x3d4 0x00 0x15 0x00 0x10059 0x168 0x3f4 0x00 0x15 0x00 0x10059 0xc0 0x34c 0x00 0x05 0x00 0x17059 0xbc 0x348 0x00 0x05 0x00 0x17059>;
						linux,phandle = <0x21>;
						phandle = <0x21>;
					};

					tps65185_gpio_sleep_grp {
						fsl,pins = <0x13c 0x3c8 0x00 0x15 0x00 0x10059 0x164 0x3f0 0x00 0x15 0x00 0x10059 0x148 0x3d4 0x00 0x15 0x00 0x10059 0x168 0x3f4 0x00 0x15 0x00 0x10059 0xc0 0x34c 0x00 0x05 0x00 0x13059 0xbc 0x348 0x00 0x05 0x00 0x13059>;
						linux,phandle = <0x25>;
						phandle = <0x25>;
					};

					lm3630a_bl_gpio_grp {
						fsl,pins = <0x170 0x3fc 0x00 0x05 0x00 0x17059>;
						linux,phandle = <0x23>;
						phandle = <0x23>;
					};

					usdhc1_vselect_grp {
						fsl,pins = <0x70 0x2fc 0x00 0x04 0x00 0x17059>;
					};

					usdhc2grp {
						fsl,pins = <0x17c 0x408 0x678 0x01 0x02 0x17059 0x178 0x404 0x670 0x01 0x02 0x10059 0x180 0x40c 0x67c 0x01 0x02 0x17059 0x184 0x410 0x680 0x01 0x02 0x17059 0x188 0x414 0x684 0x01 0x01 0x17059 0x18c 0x418 0x688 0x01 0x02 0x17059>;
						linux,phandle = <0x1e>;
						phandle = <0x1e>;
					};

					usdhc2grp_sleep {
						fsl,pins = <0x17c 0x408 0x678 0x01 0x02 0x10059 0x178 0x404 0x670 0x01 0x02 0x10059 0x180 0x40c 0x67c 0x01 0x02 0x10059 0x184 0x410 0x680 0x01 0x02 0x10059 0x188 0x414 0x684 0x01 0x01 0x10059 0x18c 0x418 0x688 0x01 0x02 0x10059>;
						linux,phandle = <0x1f>;
						phandle = <0x1f>;
					};

					usdhc2grp100mhz {
						fsl,pins = <0x17c 0x408 0x678 0x01 0x02 0x170b9 0x178 0x404 0x670 0x01 0x02 0x100a9 0x180 0x40c 0x67c 0x01 0x02 0x170a9 0x184 0x410 0x680 0x01 0x02 0x170a9 0x188 0x414 0x684 0x01 0x01 0x170a9 0x18c 0x418 0x688 0x01 0x02 0x170a9>;
					};

					usdhc2grp200mhz {
						fsl,pins = <0x17c 0x408 0x678 0x01 0x02 0x170f9 0x178 0x404 0x670 0x01 0x02 0x100f9 0x180 0x40c 0x67c 0x01 0x02 0x170f9 0x184 0x410 0x680 0x01 0x02 0x170f9 0x188 0x414 0x684 0x01 0x01 0x170f9 0x18c 0x418 0x688 0x01 0x02 0x170f9>;
					};

					usdhc2_rst_grp {
						fsl,pins = <0x1a0 0x42c 0x00 0x05 0x00 0x17059>;
					};

					rohm_gpio_grp {
						fsl,pins = <0x1a4 0x430 0x00 0x05 0x00 0x17059>;
						linux,phandle = <0x33>;
						phandle = <0x33>;
					};
				};
			};

			iomuxc-gpr@020e4000 {
				compatible = "fsl,imx6ul-iomuxc-gpr\0fsl,imx6q-iomuxc-gpr\0syscon";
				reg = <0x20e4000 0x4000>;
				linux,phandle = <0x09>;
				phandle = <0x09>;
			};

			mqs {
				compatible = "fsl,imx6sx-mqs";
				gpr = <0x09>;
				status = "disabled";
			};

			gpt@020e8000 {
				compatible = "fsl,imx6ul-gpt\0fsl,imx31-gpt";
				reg = <0x20e8000 0x4000>;
				interrupts = <0x00 0x6d 0x04>;
				clocks = <0x01 0x00 0x01 0x00>;
				clock-names = "ipg\0per";
			};

			sdma@020ec000 {
				compatible = "fsl,imx6ul-sdma\0fsl,imx35-sdma";
				reg = <0x20ec000 0x4000>;
				interrupts = <0x00 0x02 0x04>;
				clocks = <0x01 0xb8 0x01 0xb8>;
				clock-names = "ipg\0ahb";
				#dma-cells = <0x03>;
				iram = <0x14>;
				fsl,sdma-ram-script-name = "imx/sdma/sdma-imx6q.bin";
				linux,phandle = <0x07>;
				phandle = <0x07>;
			};

			pwm@020f0000 {
				compatible = "fsl,imx6ul-pwm\0fsl,imx27-pwm";
				reg = <0x20f0000 0x4000>;
				interrupts = <0x00 0x72 0x04>;
				clocks = <0x01 0x00 0x01 0x00>;
				clock-names = "ipg\0per";
				#pwm-cells = <0x02>;
			};

			pwm@020f4000 {
				compatible = "fsl,imx6ul-pwm\0fsl,imx27-pwm";
				reg = <0x20f4000 0x4000>;
				interrupts = <0x00 0x73 0x04>;
				clocks = <0x01 0x00 0x01 0x00>;
				clock-names = "ipg\0per";
				#pwm-cells = <0x02>;
			};

			pwm@020f8000 {
				compatible = "fsl,imx6ul-pwm\0fsl,imx27-pwm";
				reg = <0x20f8000 0x4000>;
				interrupts = <0x00 0x74 0x04>;
				clocks = <0x01 0x00 0x01 0x00>;
				clock-names = "ipg\0per";
				#pwm-cells = <0x02>;
			};

			pwm@020fc000 {
				compatible = "fsl,imx6ul-pwm\0fsl,imx27-pwm";
				reg = <0x20fc000 0x4000>;
				interrupts = <0x00 0x75 0x04>;
				clocks = <0x01 0x00 0x01 0x00>;
				clock-names = "ipg\0per";
				#pwm-cells = <0x02>;
			};
		};

		aips-bus@02100000 {
			compatible = "fsl,aips-bus\0simple-bus";
			#address-cells = <0x01>;
			#size-cells = <0x01>;
			reg = <0x2100000 0x100000>;
			ranges;

			usb@02184000 {
				compatible = "fsl,imx6ul-usb\0fsl,imx27-usb";
				reg = <0x2184000 0x200>;
				interrupts = <0x00 0x2b 0x04>;
				clocks = <0x01 0xcd>;
				fsl,usbphy = <0x15>;
				fsl,usbmisc = <0x16 0x00>;
				fsl,anatop = <0x10>;
				ahb-burst-config = <0x00>;
				tx-burst-size-dword = <0x10>;
				rx-burst-size-dword = <0x10>;
				status = "okay";
				dr_mode = "otg";
				srp-disable;
				hnp-disable;
				adp-disable;
			};

			usb@02184200 {
				compatible = "fsl,imx6ul-usb\0fsl,imx27-usb";
				reg = <0x2184200 0x200>;
				interrupts = <0x00 0x2a 0x04>;
				clocks = <0x01 0xcd>;
				fsl,usbphy = <0x17>;
				fsl,usbmisc = <0x16 0x01>;
				ahb-burst-config = <0x00>;
				tx-burst-size-dword = <0x10>;
				rx-burst-size-dword = <0x10>;
				status = "disabled";
			};

			usbmisc@02184800 {
				#index-cells = <0x01>;
				compatible = "fsl,imx6ul-usbmisc\0fsl,imx6q-usbmisc";
				reg = <0x2184800 0x200>;
				linux,phandle = <0x16>;
				phandle = <0x16>;
			};

			ethernet@02188000 {
				compatible = "fsl,imx6ul-fec\0fsl,imx6q-fec";
				reg = <0x2188000 0x4000>;
				interrupts = <0x00 0x76 0x04 0x00 0x77 0x04>;
				clocks = <0x01 0x90 0x01 0x91 0x01 0x30 0x01 0x2c 0x01 0x2c>;
				clock-names = "ipg\0ahb\0ptp\0enet_clk_ref\0enet_out";
				stop-mode = <0x09 0x10 0x03>;
				fsl,num-tx-queues = <0x01>;
				fsl,num-rx-queues = <0x01>;
				fsl,magic-packet;
				fsl,wakeup_irq = <0x00>;
				status = "disabled";
			};

			usdhc@02190000 {
				compatible = "fsl,imx6ul-usdhc\0fsl,imx6sx-usdhc";
				reg = <0x2190000 0x4000>;
				interrupts = <0x00 0x16 0x04>;
				clocks = <0x01 0xce 0x01 0xce 0x01 0xce>;
				clock-names = "ipg\0ahb\0per";
				bus-width = <0x04>;
				fsl,tuning-step = <0x02>;
				status = "okay";
				pinctrl-names = "default\0state_100mhz\0state_200mhz\0sleep";
				pinctrl-0 = <0x18 0x19>;
				pinctrl-1 = <0x1a>;
				pinctrl-2 = <0x1b>;
				pinctrl-3 = <0x1c 0x19>;
				vmmc-supply = <0x1d>;
				wifi-host;
			};

			usdhc@02194000 {
				compatible = "fsl,imx6ul-usdhc\0fsl,imx6sx-usdhc";
				reg = <0x2194000 0x4000>;
				interrupts = <0x00 0x17 0x04>;
				clocks = <0x01 0xcf 0x01 0xcf 0x01 0xcf>;
				clock-names = "ipg\0ahb\0per";
				bus-width = <0x04>;
				fsl,tuning-step = <0x02>;
				status = "okay";
				pinctrl-names = "default\0sleep";
				pinctrl-0 = <0x1e>;
				pinctrl-1 = <0x1f>;
				non-removable;
				no-1-8-v;
				keep-power-in-suspend;
			};

			adc@02198000 {
				compatible = "fsl,imx6ul-adc\0fsl,vf610-adc";
				reg = <0x2198000 0x4000>;
				interrupts = <0x00 0x64 0x04>;
				clocks = <0x01 0x7b>;
				num-channels = <0x02>;
				clock-names = "adc";
				status = "disabled";
			};

			i2c@021a0000 {
				#address-cells = <0x01>;
				#size-cells = <0x00>;
				compatible = "fsl,imx6ul-i2c\0fsl,imx21-i2c";
				reg = <0x21a0000 0x4000>;
				interrupts = <0x00 0x24 0x04>;
				clocks = <0x01 0x9c>;
				status = "okay";
				clock-frequency = <0x186a0>;
				pinctrl-names = "default\0sleep";
				pinctrl-0 = <0x20 0x21 0x22 0x23>;
				pinctrl-1 = <0x24 0x25 0x26>;

				elan_ts@15 {
					compatible = "elan,elan-touch";
					reg = <0x15>;
					gpio_intr = <0x27 0x07 0x00>;
					gpio_elan_rst = <0x27 0x06 0x00>;
				};

				lm3630a-i2c@36 {
					reg = <0x36>;
					compatible = "ti,lm3630a_bl";
					gpios = <0x28 0x1b 0x00>;
				};

				tps6518x@68 {
					compatible = "ti,tps6518x";
					reg = <0x68>;
					pwr_seq0 = <0xe1>;
					pwr_seq1 = <0x30>;
					pwr_seq2 = <0x33>;
					upseq0 = <0xe1>;
					upseq1 = <0x00>;
					dwnseq0 = <0x1e>;
					dwnseq1 = <0xe0>;
					gpio_pmic_pwrgood = <0x29 0x0d 0x00>;
					gpio_pmic_vcom_ctrl = <0x29 0x03 0x00>;
					gpio_pmic_wakeup = <0x29 0x07 0x00>;
					gpio_pmic_powerup = <0x29 0x08 0x00>;
					gpio_pmic_intr = <0x29 0x09 0x00>;
					gpio_pmic_pwrall = <0x29 0x0e 0x00>;

					regulators {

						DISPLAY {
							regulator-name = "DISPLAY";
							linux,phandle = <0x3a>;
							phandle = <0x3a>;
						};

						VCOM {
							regulator-name = "VCOM";
							regulator-min-microvolt = <0xffbe0178>;
							regulator-max-microvolt = <0xfff85ee0>;
							linux,phandle = <0x39>;
							phandle = <0x39>;
						};

						V3P3 {
							regulator-name = "V3P3";
							linux,phandle = <0x38>;
							phandle = <0x38>;
						};

						TMST {
							regulator-name = "TMST";
							linux,phandle = <0x3b>;
							phandle = <0x3b>;
						};
					};
				};

				sy7636@62 {
					compatible = "Silergy,sy7636";
					reg = <0x62>;
					on_delay1 = <0x02>;
					on_delay2 = <0x02>;
					on_delay3 = <0x02>;
					on_delay4 = <0x02>;
					turnoff_delay_ep3v3 = <0x64>;
					gpio_pmic_pwrgood = <0x27 0x0d 0x00>;
					gpio_pmic_vcom_ctrl = <0x28 0x18 0x00>;
					gpio_pmic_powerup = <0x28 0x19 0x00>;
					gpio_pmic_pwrall = <0x28 0x0e 0x00>;

					regulators {

						DISPLAY_SY7636 {
							regulator-name = "DISPLAY_SY7636";
						};

						VCOM_SY7636 {
							regulator-name = "VCOM_SY7636";
							regulator-min-microvolt = <0xffbe0178>;
							regulator-max-microvolt = <0xfff85ee0>;
						};

						V3P3_SY7636 {
							regulator-name = "V3P3_SY7636";
						};

						TMST_SY7636 {
							regulator-name = "TMST_SY7636";
						};
					};
				};
			};

			i2c@021a4000 {
				#address-cells = <0x01>;
				#size-cells = <0x00>;
				compatible = "fsl,imx6ul-i2c\0fsl,imx21-i2c";
				reg = <0x21a4000 0x4000>;
				interrupts = <0x00 0x25 0x04>;
				clocks = <0x01 0x9d>;
				status = "disabled";
			};

			i2c@021a8000 {
				#address-cells = <0x01>;
				#size-cells = <0x00>;
				compatible = "fsl,imx6ul-i2c\0fsl,imx21-i2c";
				reg = <0x21a8000 0x4000>;
				interrupts = <0x00 0x26 0x04>;
				clocks = <0x01 0x9e>;
				status = "disabled";
			};

			romcp@021ac000 {
				compatible = "fsl,imx6ul-romcp\0syscon";
				reg = <0x21ac000 0x4000>;
			};

			mmdc@021b0000 {
				compatible = "fsl,imx6ul-mmdc\0fsl,imx6q-mmdc";
				reg = <0x21b0000 0x4000>;
			};

			weim@021b8000 {
				compatible = "fsl,imx6ul-weim\0fsl,imx6q-weim";
				reg = <0x21b8000 0x4000>;
				interrupts = <0x00 0x0e 0x04>;
				clocks = <0x01 0x00>;
			};

			ocotp-ctrl@021bc000 {
				compatible = "fsl,imx6ull-ocotp\0syscon";
				reg = <0x21bc000 0x4000>;
				clocks = <0x01 0xa5>;
				linux,phandle = <0x11>;
				phandle = <0x11>;
			};

			csu@021c0000 {
				compatible = "fsl,imx6ul-csu";
				reg = <0x21c0000 0x4000>;
				interrupts = <0x00 0x15 0x04>;
				status = "disabled";
			};

			csi@021c4000 {
				compatible = "fsl,imx6ul-csi\0fsl,imx6s-csi";
				reg = <0x21c4000 0x4000>;
				interrupts = <0x00 0x07 0x04>;
				clocks = <0x01 0x00 0x01 0x8a 0x01 0x00>;
				clock-names = "disp-axi\0csi_mclk\0disp_dcic";
				status = "disabled";
			};

			lcdif@021c8000 {
				compatible = "fsl,imx6ul-lcdif\0fsl,imx28-lcdif";
				reg = <0x21c8000 0x4000>;
				interrupts = <0x00 0x05 0x04>;
				clocks = <0x01 0xa2 0x01 0xa1 0x01 0x00>;
				clock-names = "pix\0axi\0disp_axi";
				status = "disabled";
				pinctrl-names = "default";
				pinctrl-0 = <0x2a 0x2b>;
				display = <0x2c>;

				display {
					bits-per-pixel = <0x10>;
					bus-width = <0x18>;
					linux,phandle = <0x2c>;
					phandle = <0x2c>;

					display-timings {
						native-mode = <0x2d>;

						timing0 {
							clock-frequency = <0x1ff2b60>;
							hactive = <0x320>;
							vactive = <0x1e0>;
							hback-porch = <0x59>;
							hfront-porch = <0xa4>;
							vback-porch = <0x17>;
							vfront-porch = <0x0a>;
							hsync-len = <0x0a>;
							vsync-len = <0x0a>;
							hsync-active = <0x00>;
							vsync-active = <0x00>;
							de-active = <0x01>;
							pixelclk-active = <0x00>;
							linux,phandle = <0x2d>;
							phandle = <0x2d>;
						};
					};
				};
			};

			pxp@021cc000 {
				compatible = "fsl,imx6ull-pxp-dma\0fsl,imx7d-pxp-dma";
				reg = <0x21cc000 0x4000>;
				interrupts = <0x00 0x08 0x04 0x00 0x12 0x04>;
				clocks = <0x01 0x00 0x01 0xaf>;
				clock-names = "pxp_ipg\0pxp_axi";
				status = "okay";
			};

			qspi@021e0000 {
				#address-cells = <0x01>;
				#size-cells = <0x00>;
				compatible = "fsl,imx6ull-qspi\0fsl,imx6ul-qspi";
				reg = <0x21e0000 0x4000 0x60000000 0x10000000>;
				reg-names = "QuadSPI\0QuadSPI-memory";
				interrupts = <0x00 0x6b 0x04>;
				clocks = <0x01 0xb0 0x01 0xb0>;
				clock-names = "qspi_en\0qspi";
				status = "disabled";
				pinctrl-names = "default";
				pinctrl-0 = <0x2e>;
				ddrsmp = <0x00>;
			};

			serial@021e8000 {
				compatible = "fsl,imx6ul-uart\0fsl,imx6q-uart\0fsl,imx21-uart";
				reg = <0x21e8000 0x4000>;
				interrupts = <0x00 0x1b 0x04>;
				clocks = <0x01 0xbf 0x01 0xc0>;
				clock-names = "ipg\0per";
				dmas = <0x07 0x1b 0x04 0x00 0x07 0x1c 0x04 0x00>;
				dma-names = "rx\0tx";
				status = "disabled";
				pinctrl-names = "default";
				fsl,uart-has-rtscts;
				fsl,dte-mode;
			};

			serial@021ec000 {
				compatible = "fsl,imx6ul-uart\0fsl,imx6q-uart\0fsl,imx21-uart";
				reg = <0x21ec000 0x4000>;
				interrupts = <0x00 0x1c 0x04>;
				clocks = <0x01 0xc1 0x01 0xc2>;
				clock-names = "ipg\0per";
				dmas = <0x07 0x1d 0x04 0x00 0x07 0x1e 0x04 0x00>;
				dma-names = "rx\0tx";
				status = "okay";
				pinctrl-names = "default\0sleep";
				fsl,uart-has-rtscts;
				fsl,dte-mode;
				pinctrl-0 = <0x2f 0x30>;
				pinctrl-1 = <0x31>;
			};

			serial@021f0000 {
				compatible = "fsl,imx6ul-uart\0fsl,imx6q-uart\0fsl,imx21-uart";
				reg = <0x21f0000 0x4000>;
				interrupts = <0x00 0x1d 0x04>;
				clocks = <0x01 0xc3 0x01 0xc4>;
				clock-names = "ipg\0per";
				dmas = <0x07 0x1f 0x04 0x00 0x07 0x20 0x04 0x00>;
				dma-names = "rx\0tx";
				status = "disabled";
			};

			serial@021f4000 {
				compatible = "fsl,imx6ul-uart\0fsl,imx6q-uart\0fsl,imx21-uart";
				reg = <0x21f4000 0x4000>;
				interrupts = <0x00 0x1e 0x04>;
				clocks = <0x01 0xc5 0x01 0xc6>;
				clock-names = "ipg\0per";
				dmas = <0x07 0x21 0x04 0x00 0x07 0x22 0x04 0x00>;
				dma-names = "rx\0tx";
				status = "disabled";
			};

			i2c@021f8000 {
				#address-cells = <0x01>;
				#size-cells = <0x00>;
				compatible = "fsl,imx6ul-i2c\0fsl,imx21-i2c";
				reg = <0x21f8000 0x4000>;
				interrupts = <0x00 0x23 0x04>;
				clocks = <0x01 0x9f>;
				status = "okay";
				clock-frequency = <0x186a0>;
				pinctrl-names = "default";
				pinctrl-0 = <0x32 0x33 0x34>;

				bd71828-i2c@4b {
					reg = <0x4b>;
					compatible = "rohm,bd71828";
					gpio_int = <0x35 0x01 0x01>;
					gpio_wdogb = <0x36 0x0b 0x01>;
					rohm,charger-sense-resistor-ohms = <0x1406f40>;
					#address-cells = <0x01>;
					#size-cells = <0x00>;

					pmic@4b {
						compatible = "rohm,bd71828";
						reg = <0x4b>;
						#interrupt-parent = <0x27>;
						#interrupts = <0x1d 0x08>;
						#clocks = <0x0c 0x00>;
						#clock-cells = <0x00>;
						#clock-output-names = "bd71828-32k-out";
						#gpio-controller;
						#gpio-cells = <0x02>;
						#gpio-reserved-ranges = <0x00 0x01 0x02 0x01>;
						#rohm,dvs-vsel-gpios = <0x27 0x0c 0x00 0x27 0x0d 0x00>;
						rohm,charger-sense-resistor-ohms = <0x989680>;

						leds {
							compatible = "rohm,bd71828-leds";

							led-1 {
								rohm,led-compatible = "bd71828-grnled";
								function = "indicator";
								color = <0x02>;
							};

							led-2 {
								rohm,led-compatible = "bd71828-ambled";
								function = "charging";
								color = <0x04>;
							};
						};
					};

					regulators {

						BUCK1 {
							regulator-name = "buck1";
							regulator-min-microvolt = <0x7a120>;
							regulator-max-microvolt = <0x155cc0>;
							regulator-boot-on;
							regulator-always-on;
						};

						BUCK2 {
							regulator-name = "buck2";
							regulator-min-microvolt = <0x7a120>;
							regulator-max-microvolt = <0x1e8480>;
							regulator-boot-on;
							regulator-always-on;
						};

						BUCK3 {
							regulator-name = "buck3";
							regulator-min-microvolt = <0x124f80>;
							regulator-max-microvolt = <0x1b7740>;
							regulator-boot-on;
							regulator-always-on;
						};

						BUCK4 {
							regulator-name = "buck4";
							regulator-min-microvolt = <0xf4240>;
							regulator-max-microvolt = <0x124f80>;
							regulator-boot-on;
							regulator-always-on;
						};

						BUCK5 {
							regulator-name = "buck5";
							regulator-min-microvolt = <0x2625a0>;
							regulator-max-microvolt = <0x325aa0>;
							regulator-boot-on;
							regulator-always-on;
						};

						BUCK6 {
							regulator-name = "buck6";
							regulator-min-microvolt = <0x7a120>;
							regulator-max-microvolt = <0x1e8480>;
							regulator-boot-off;
							regulator-always-on;
						};

						BUCK7 {
							regulator-name = "buck7";
							regulator-min-microvolt = <0x7a120>;
							regulator-max-microvolt = <0x1e8480>;
							regulator-boot-off;
							regulator-always-on;
						};

						LDO1 {
							regulator-name = "ldo1";
							regulator-min-microvolt = "\0\f5";
							regulator-max-microvolt = <0x325aa0>;
							regulator-boot-on;
							regulator-always-on;
						};

						LDO2 {
							regulator-name = "ldo2";
							regulator-min-microvolt = "\0\f5";
							regulator-max-microvolt = <0x325aa0>;
							regulator-boot-off;
							regulator-always-on;
						};

						LDO3 {
							regulator-name = "ldo3";
							regulator-min-microvolt = "\0\f5";
							regulator-max-microvolt = <0x325aa0>;
							regulator-boot-on;
							regulator-always-on;
						};

						LDO4 {
							regulator-name = "ldo4";
							regulator-min-microvolt = "\0\f5";
							regulator-max-microvolt = <0x325aa0>;
							regulator-boot-off;
							regulator-always-on;
						};

						LDO5 {
							regulator-name = "ldo5";
							regulator-min-microvolt = "\0\f5";
							regulator-max-microvolt = <0x325aa0>;
							regulator-boot-off;
							regulator-always-on;
						};

						LDO6 {
							regulator-name = "ldo6";
							regulator-min-microvolt = <0x1b7740>;
							regulator-max-microvolt = <0x1b7740>;
							regulator-boot-off;
							regulator-always-on;
						};

						LDO7 {
							regulator-name = "ldo7";
							regulator-min-microvolt = "\0\f5";
							regulator-max-microvolt = <0x325aa0>;
							regulator-boot-on;
							regulator-always-on;
						};
					};
				};
			};

			serial@021fc000 {
				compatible = "fsl,imx6ul-uart\0fsl,imx6q-uart\0fsl,imx21-uart";
				reg = <0x21fc000 0x4000>;
				interrupts = <0x00 0x11 0x04>;
				clocks = <0x01 0xc7 0x01 0xc8>;
				clock-names = "ipg\0per";
				dmas = <0x07 0x00 0x04 0x00 0x07 0x2f 0x04 0x00>;
				dma-names = "rx\0tx";
				status = "disabled";
			};
		};

		aips-bus@02200000 {
			compatible = "fsl,aips-bus\0simple-bus";
			#address-cells = <0x01>;
			#size-cells = <0x01>;
			reg = <0x2200000 0x100000>;
			ranges;

			dcp@02280000 {
				compatible = "fsl,imx6sl-dcp";
				reg = <0x2280000 0x4000>;
				interrupts = <0x00 0x2e 0x04 0x00 0x2f 0x04 0x00 0x30 0x04>;
				clocks = <0x01 0xe6>;
				clock-names = "dcp";
			};

			rngb@02284000 {
				compatible = "fsl,imx6sl-rng\0fsl,imx-rng\0imx-rng";
				reg = <0x2284000 0x4000>;
				interrupts = <0x00 0x06 0x04>;
				clocks = <0x01 0x00>;
			};

			serial@02288000 {
				compatible = "fsl,imx6ul-uart\0fsl,imx6q-uart\0fsl,imx21-uart";
				reg = <0x2288000 0x4000>;
				interrupts = <0x00 0x28 0x04>;
				clocks = <0x01 0xcb 0x01 0xcc>;
				clock-names = "ipg\0per";
				dmas = <0x07 0x2d 0x04 0x00 0x07 0x2e 0x04 0x00>;
				dma-names = "rx\0tx";
				status = "disabled";
			};

			epdc@0228c000 {
				compatible = "fsl,imx7d-epdc";
				interrupts = <0x00 0x70 0x04>;
				reg = <0x228c000 0x4000>;
				clocks = <0x01 0xea 0x01 0xeb>;
				clock-names = "epdc_axi\0epdc_pix";
				status = "okay";
				safe-ticks-turnoff-ep3v3 = <0x190>;
				pinctrl-names = "default";
				pinctrl-0 = <0x37>;
				V3P3-supply = <0x38>;
				VCOM-supply = <0x39>;
				DISPLAY-supply = <0x3a>;
				TMST-supply = <0x3b>;
			};

			iomuxc-snvs@02290000 {
				compatible = "fsl,imx6ull-iomuxc-snvs";
				reg = <0x2290000 0x10000>;

				imx6ul-ddr3-arm2 {

					gpio_snvs_keys_grp {
						fsl,pins = <0x10 0x54 0x00 0x05 0x00 0x17059 0x18 0x5c 0x00 0x05 0x00 0x17059 0x14 0x2a0 0x00 0x05 0x00 0x80000000>;
						linux,phandle = <0x3d>;
						phandle = <0x3d>;
					};

					led_grp {
						fsl,pins = <0x1c 0x60 0x00 0x05 0x00 0x80000000>;
						linux,phandle = <0x3c>;
						phandle = <0x3c>;
					};

					rohm_snvs_gpio_grp {
						fsl,pins = <0x0c 0x50 0x00 0x05 0x00 0x17059>;
						linux,phandle = <0x34>;
						phandle = <0x34>;
					};

					usdhc1_pwr_grp {
						fsl,pins = <0x20 0x64 0x00 0x05 0x00 0x10059 0x24 0x68 0x00 0x05 0x00 0x10059 0x28 0x6c 0x00 0x05 0x00 0x10059>;
						linux,phandle = <0x19>;
						phandle = <0x19>;
					};
				};
			};

			snvs-gpr@0x02294000 {
				compatible = "fsl, imx6ull-snvs-gpr";
				reg = <0x2294000 0x10000>;
			};
		};
	};

	pxp_v4l2 {
		compatible = "fsl,imx6ul-pxp-v4l2\0fsl,imx6sx-pxp-v4l2\0fsl,imx6sl-pxp-v4l2";
		status = "okay";
	};

	regulators {
		compatible = "simple-bus";
		#address-cells = <0x01>;
		#size-cells = <0x00>;

		regulator@1 {
			compatible = "regulator-fixed";
			regulator-name = "vref-3v3";
			regulator-min-microvolt = <0x325aa0>;
			regulator-max-microvolt = <0x325aa0>;
		};

		wifi_regulator {
			compatible = "regulator-fixed";
			regulator-name = "SD1_SPWR";
			regulator-min-microvolt = <0x2dc6c0>;
			regulator-max-microvolt = <0x2dc6c0>;
			wifipwr-gpio = <0x35 0x08 0x01>;
			wifidis-gpio = <0x36 0x17 0x00>;
			wifirst-gpio = <0x35 0x07 0x00>;
			wifiint-gpio = <0x35 0x06 0x00>;
			btdis-gpio = <0x36 0x16 0x00>;
			btint-gpio = <0x36 0x18 0x00>;
			linux,phandle = <0x1d>;
			phandle = <0x1d>;
		};
	};

	leds {
		compatible = "gpio-leds";
		pinctrl-names = "default";
		pinctrl-0 = <0x3c>;

		user {
			label = "GLED";
			gpios = <0x35 0x05 0x01>;
			linux,default-trigger = "timer";
		};
	};

	gpio-keys {
		compatible = "gpio-keys";
		pinctrl-names = "default";
		pinctrl-0 = <0x3d>;

		hall {
			label = "Hall";
			gpios = <0x35 0x02 0x01>;
			linux,code = <0x23>;
			gpio-key,wakeup;
		};
	};

	usb_plug {
		compatible = "usb_plug";
	};

	ntx_bl {
		compatible = "ntx_bl";
	};

	ntx_led {
		compatible = "ntx_led";
	};

	ntx_event0 {
		compatible = "ntx_event0";
	};
};
